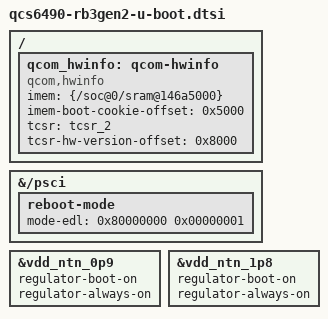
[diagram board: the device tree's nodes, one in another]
// SPDX-License-Identifier: BSD-3-Clause
/*
 * Copyright (c) 2024 Linaro Ltd.
 */
/ {
	/* IMEM boot cookie + TCSR HW version offsets */
	qcom_hwinfo: qcom-hwinfo {
		compatible = "qcom,hwinfo";

		imem = <&{/soc@0/sram@146a5000}>;
		imem-boot-cookie-offset = <0x5000>;

		tcsr = <&tcsr_2>;
		tcsr-hw-version-offset = <0x8000>;
	};
};

/* Enter Qualcomm EDL/download mode via "reset -edl". */
&{/psci} {
	reboot-mode {
		mode-edl = <0x80000000 0x00000001>;
	};
};

&vdd_ntn_0p9 {
	regulator-boot-on;
	regulator-always-on;
};

&vdd_ntn_1p8 {
	regulator-boot-on;
	regulator-always-on;
};
